# STM32F102 register map
File version: 1.2
CPU: CM3 r1p1, little endian, no MPU, no FPU, 4 interrupt priority bits
Registers are 32-bit, read-write, reset 0x0 unless marked. A register's access mark holds for its fields unless they carry their own. Offsets are from the block's base; [hi:lo] are bit positions.

## TIM9 — General purpose timer
Base 0x40014C00
Same registers: TIM12 0x40001800
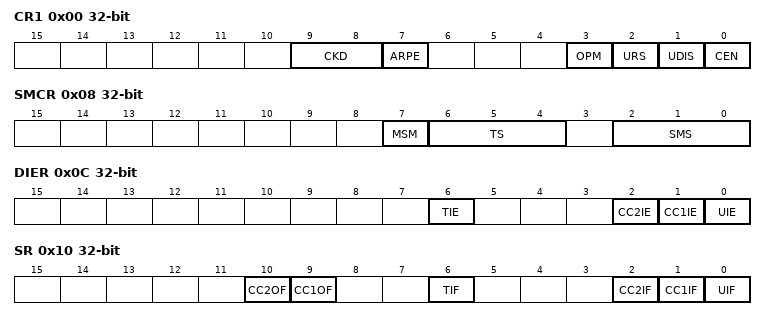
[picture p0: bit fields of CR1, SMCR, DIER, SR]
0x00 CR1 — control register 1
  [9:8] CKD — Clock division
  [7] ARPE — Auto-reload preload enable
  [3] OPM — One-pulse mode
  [2] URS — Update request source
  [1] UDIS — Update disable
  [0] CEN — Counter enable
0x04 CR2 — control register 2
  [6:4] MMS — Master mode selection
0x08 SMCR — slave mode control register
  [7] MSM — Master/Slave mode
  [6:4] TS — Trigger selection
  [2:0] SMS — Slave mode selection
0x0C DIER — DMA/Interrupt enable register
  [6] TIE — Trigger interrupt enable
  [2] CC2IE — Capture/Compare 2 interrupt enable
  [1] CC1IE — Capture/Compare 1 interrupt enable
  [0] UIE — Update interrupt enable
0x10 SR — status register
  [10] CC2OF — Capture/compare 2 overcapture flag
  [9] CC1OF — Capture/Compare 1 overcapture flag
  [6] TIF — Trigger interrupt flag
  [2] CC2IF — Capture/Compare 2 interrupt flag
  [1] CC1IF — Capture/compare 1 interrupt flag
  [0] UIF — Update interrupt flag
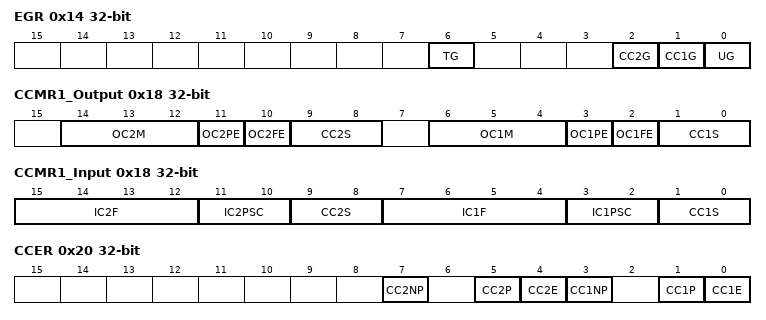
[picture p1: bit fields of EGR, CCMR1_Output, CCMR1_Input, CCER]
0x14 EGR wo — event generation register
  [6] TG — Trigger generation
  [2] CC2G — Capture/compare 2 generation
  [1] CC1G — Capture/compare 1 generation
  [0] UG — Update generation
0x18 CCMR1_Output — capture/compare mode register 1 (output mode)
  [14:12] OC2M — Output Compare 2 mode
  [11] OC2PE — Output Compare 2 preload enable
  [10] OC2FE — Output Compare 2 fast enable
  [9:8] CC2S — Capture/Compare 2 selection
  [6:4] OC1M — Output Compare 1 mode
  [3] OC1PE — Output Compare 1 preload enable
  [2] OC1FE — Output Compare 1 fast enable
  [1:0] CC1S — Capture/Compare 1 selection
0x18 CCMR1_Input (alternate view of CCMR1_Output) — capture/compare mode register 1 (input mode)
  [15:12] IC2F — Input capture 2 filter
  [11:10] IC2PSC — Input capture 2 prescaler
  [9:8] CC2S — Capture/Compare 2 selection
  [7:4] IC1F — Input capture 1 filter
  [3:2] IC1PSC — Input capture 1 prescaler
  [1:0] CC1S — Capture/Compare 1 selection
0x20 CCER — capture/compare enable register
  [7] CC2NP — Capture/Compare 2 output Polarity
  [5] CC2P — Capture/Compare 2 output Polarity
  [4] CC2E — Capture/Compare 2 output enable
  [3] CC1NP — Capture/Compare 1 output Polarity
  [1] CC1P — Capture/Compare 1 output Polarity
  [0] CC1E — Capture/Compare 1 output enable
0x24 CNT — counter
  [15:0] CNT — counter value
0x28 PSC — prescaler
  [15:0] PSC — Prescaler value
0x2C ARR — auto-reload register
  [15:0] ARR — Auto-reload value
0x34 CCR1 — capture/compare register 1
  [15:0] CCR1 — Capture/Compare 1 value
0x38 CCR2 — capture/compare register 2
  [15:0] CCR2 — Capture/Compare 2 value

## DAC — Digital to analog converter
Base 0x40007400
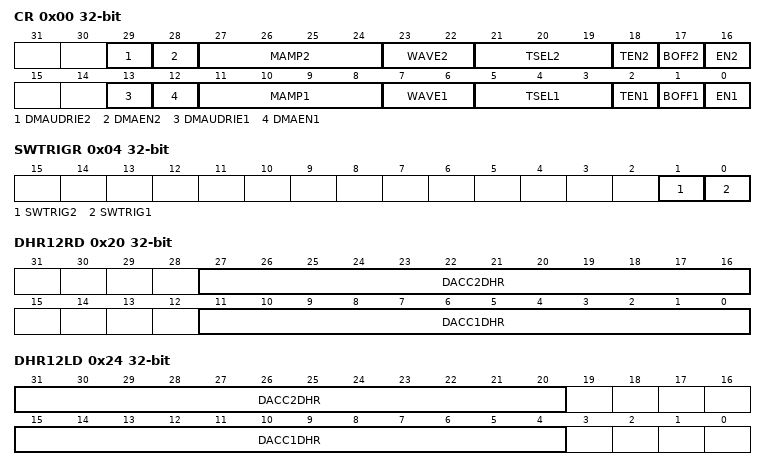
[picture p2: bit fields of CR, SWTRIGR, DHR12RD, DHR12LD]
0x00 CR — Control register (DAC_CR)
  [29] DMAUDRIE2 — DAC channel2 DMA underrun interrupt enable
  [28] DMAEN2 — DAC channel2 DMA enable
  [27:24] MAMP2 — DAC channel2 mask/amplitude selector
  [23:22] WAVE2 — DAC channel2 noise/triangle wave generation enable
  [21:19] TSEL2 — DAC channel2 trigger selection
  [18] TEN2 — DAC channel2 trigger enable
  [17] BOFF2 — DAC channel2 output buffer disable
  [16] EN2 — DAC channel2 enable
  [13] DMAUDRIE1 — DAC channel1 DMA underrun interrupt enable
  [12] DMAEN1 — DAC channel1 DMA enable
  [11:8] MAMP1 — DAC channel1 mask/amplitude selector
  [7:6] WAVE1 — DAC channel1 noise/triangle wave generation enable
  [5:3] TSEL1 — DAC channel1 trigger selection
  [2] TEN1 — DAC channel1 trigger enable
  [1] BOFF1 — DAC channel1 output buffer disable
  [0] EN1 — DAC channel1 enable
0x04 SWTRIGR wo — DAC software trigger register (DAC_SWTRIGR)
  [1] SWTRIG2 — DAC channel2 software trigger
  [0] SWTRIG1 — DAC channel1 software trigger
0x08 DHR12R1 — DAC channel1 12-bit right-aligned data holding register(DAC_DHR12R1)
  [11:0] DACC1DHR — DAC channel1 12-bit right-aligned data
0x0C DHR12L1 — DAC channel1 12-bit left aligned data holding register (DAC_DHR12L1)
  [15:4] DACC1DHR — DAC channel1 12-bit left-aligned data
0x10 DHR8R1 — DAC channel1 8-bit right aligned data holding register (DAC_DHR8R1)
  [7:0] DACC1DHR — DAC channel1 8-bit right-aligned data
0x14 DHR12R2 — DAC channel2 12-bit right aligned data holding register (DAC_DHR12R2)
  [11:0] DACC2DHR — DAC channel2 12-bit right-aligned data
0x18 DHR12L2 — DAC channel2 12-bit left aligned data holding register (DAC_DHR12L2)
  [15:4] DACC2DHR — DAC channel2 12-bit left-aligned data
0x1C DHR8R2 — DAC channel2 8-bit right-aligned data holding register (DAC_DHR8R2)
  [7:0] DACC2DHR — DAC channel2 8-bit right-aligned data
0x20 DHR12RD — Dual DAC 12-bit right-aligned data holding register (DAC_DHR12RD), Bits 31:28 Reserved, Bits 15:12 Reserved
  [27:16] DACC2DHR — DAC channel2 12-bit right-aligned data
  [11:0] DACC1DHR — DAC channel1 12-bit right-aligned data
0x24 DHR12LD — DUAL DAC 12-bit left aligned data holding register (DAC_DHR12LD), Bits 19:16 Reserved, Bits 3:0 Reserved
  [31:20] DACC2DHR — DAC channel2 12-bit right-aligned data
  [15:4] DACC1DHR — DAC channel1 12-bit left-aligned data
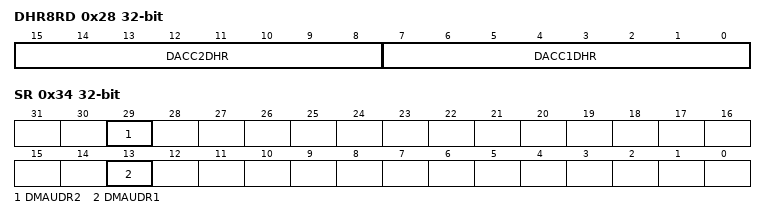
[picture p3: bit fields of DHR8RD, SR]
0x28 DHR8RD — DUAL DAC 8-bit right aligned data holding register (DAC_DHR8RD), Bits 31:16 Reserved
  [15:8] DACC2DHR — DAC channel2 8-bit right-aligned data
  [7:0] DACC1DHR — DAC channel1 8-bit right-aligned data
0x2C DOR1 ro — DAC channel1 data output register (DAC_DOR1)
  [11:0] DACC1DOR — DAC channel1 data output
0x30 DOR2 ro — DAC channel2 data output register (DAC_DOR2)
  [11:0] DACC2DOR — DAC channel2 data output
0x34 SR — DAC status register
  [29] DMAUDR2 — DAC channel2 DMA underrun flag
  [13] DMAUDR1 — DAC channel1 DMA underrun flag
